AUTOSAR XML (schema 00051)
package /S01UCON/Swc
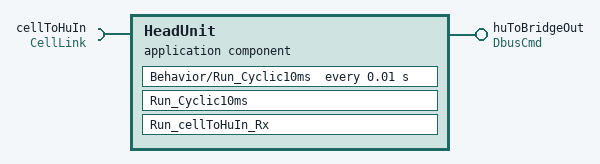
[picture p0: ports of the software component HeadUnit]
  application sw component type HeadUnit  # Application software component type HeadUnit
    require port cellToHuIn: required-interface=CellLink
    provide port huToBridgeOut: provided-interface=DbusCmd
    behavior Behavior
      data received event Dre_cellToHuIn: start-on-event=Run_cellToHuIn_Rx, data=cellToHuIn.val
      timing event Tev_Cyclic10ms: start-on-event=Behavior/Run_Cyclic10ms, period=0.01
      runnable Run_Cyclic10ms
        data-send-points:
          access Snd_huToBridgeOut: accessed-variable=huToBridgeOut.val
      runnable Run_cellToHuIn_Rx
        data-receive-point-by-arguments:
          access Rcv_cellToHuIn: accessed-variable=cellToHuIn.val
  swc implementation HeadUnit_Impl: programming-language=C, sw-version=1.0.0, behavior=HeadUnit/Behavior
  composition sw component type Root  # Composition Root
    4 x component:
      bridge: type=V850Bridge
      ivi: type=HeadUnit
      steer: type=SteeringCtrl
      tel: type=Telematics
    connect bridge.bridgeToSteerOut -> steer.bridgeToSteerIn
    connect tel.cellToHuOut -> ivi.cellToHuIn
    connect ivi.huToBridgeOut -> bridge.huToBridgeIn
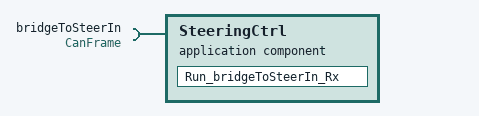
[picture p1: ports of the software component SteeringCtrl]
  application sw component type SteeringCtrl  # Application software component type SteeringCtrl
    require port bridgeToSteerIn: required-interface=CanFrame
    behavior Behavior
      data received event Dre_bridgeToSteerIn: start-on-event=Run_bridgeToSteerIn_Rx, data=bridgeToSteerIn.val
      runnable Run_bridgeToSteerIn_Rx
        data-receive-point-by-arguments:
          access Rcv_bridgeToSteerIn: accessed-variable=bridgeToSteerIn.val
  swc implementation SteeringCtrl_Impl: programming-language=C, sw-version=1.0.0, behavior=SteeringCtrl/Behavior
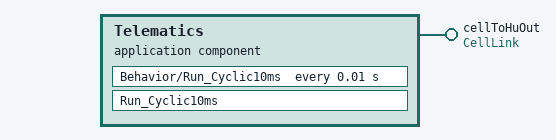
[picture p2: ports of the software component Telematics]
  application sw component type Telematics  # Application software component type Telematics
    provide port cellToHuOut: provided-interface=CellLink
    behavior Behavior
      timing event Tev_Cyclic10ms: start-on-event=Behavior/Run_Cyclic10ms, period=0.01
      runnable Run_Cyclic10ms
        data-send-points:
          access Snd_cellToHuOut: accessed-variable=cellToHuOut.val
  swc implementation Telematics_Impl: programming-language=C, sw-version=1.0.0, behavior=Telematics/Behavior
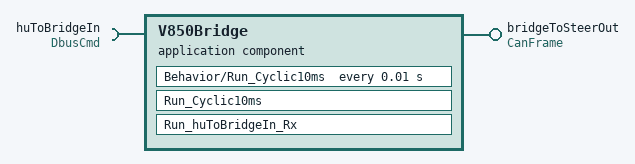
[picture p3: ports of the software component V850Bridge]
  application sw component type V850Bridge  # Application software component type V850Bridge
    provide port bridgeToSteerOut: provided-interface=CanFrame
    require port huToBridgeIn: required-interface=DbusCmd
    behavior Behavior
      data received event Dre_huToBridgeIn: start-on-event=Run_huToBridgeIn_Rx, data=huToBridgeIn.val
      timing event Tev_Cyclic10ms: start-on-event=Behavior/Run_Cyclic10ms, period=0.01
      runnable Run_Cyclic10ms
        data-send-points:
          access Snd_bridgeToSteerOut: accessed-variable=bridgeToSteerOut.val
      runnable Run_huToBridgeIn_Rx
        data-receive-point-by-arguments:
          access Rcv_huToBridgeIn: accessed-variable=huToBridgeIn.val
  swc implementation V850Bridge_Impl: programming-language=C, sw-version=1.0.0, behavior=V850Bridge/Behavior
